# ATmega32U4 register map
File version: 1.0
Registers are 8-bit, read-write, reset 0x0 unless marked. A register's access mark holds for its fields unless they carry their own. Offsets are from the block's base; [hi:lo] are bit positions; {n}, {i} and the like mark numbered series.

## TC4 — Timer/Counter, 10-bit
Base 0x00800000
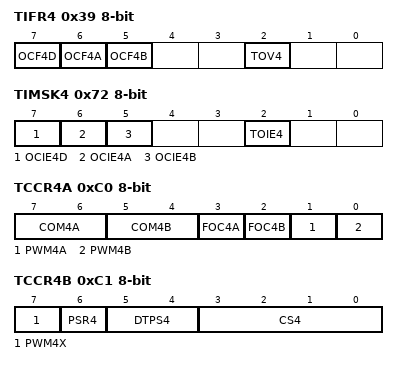
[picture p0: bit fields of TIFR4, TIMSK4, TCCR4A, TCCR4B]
0x39 TIFR4 — Timer/Counter4 Interrupt Flag register
  [7] OCF4D — Output Compare Flag 4D
  [6] OCF4A — Output Compare Flag 4A
  [5] OCF4B — Output Compare Flag 4B
  [2] TOV4 — Timer/Counter4 Overflow Flag
0x72 TIMSK4 — Timer/Counter4 Interrupt Mask Register
  [7] OCIE4D — Timer/Counter4 Output Compare D Match Interrupt Enable
  [6] OCIE4A — Timer/Counter4 Output Compare A Match Interrupt Enable
  [5] OCIE4B — Timer/Counter4 Output Compare B Match Interrupt Enable
  [2] TOIE4 — Timer/Counter4 Overflow Interrupt Enable
0xBE TCNT4 — Timer/Counter4 Low Bytes
0xBF TC4H — Timer/Counter4
0xC0 TCCR4A — Timer/Counter4 Control Register A
  [7:6] COM4A — Compare Output Mode 1A, bits
  [5:4] COM4B — Compare Output Mode 4B, bits
  [3] FOC4A — Force Output Compare Match 4A
  [2] FOC4B — Force Output Compare Match 4B
  [1] PWM4A
  [0] PWM4B
0xC1 TCCR4B — Timer/Counter4 Control Register B
  [7] PWM4X — PWM Inversion Mode
  [6] PSR4 — Prescaler Reset Timer/Counter 4
  [5:4] DTPS4 — Dead Time Prescaler Bits
  [3:0] CS4 — Clock Select Bits
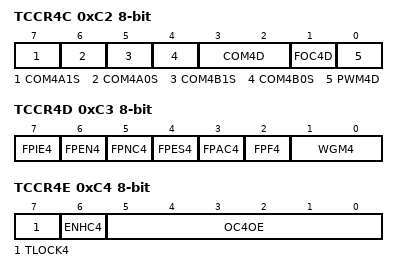
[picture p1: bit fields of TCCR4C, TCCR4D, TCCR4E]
0xC2 TCCR4C — Timer/Counter 4 Control Register C
  [7] COM4A1S — Comparator A Output Mode
  [6] COM4A0S — Comparator A Output Mode
  [5] COM4B1S — Comparator B Output Mode
  [4] COM4B0S — Comparator B Output Mode
  [3:2] COM4D — Comparator D Output Mode
  [1] FOC4D — Force Output Compare Match 4D
  [0] PWM4D — Pulse Width Modulator D Enable
0xC3 TCCR4D — Timer/Counter 4 Control Register D
  [7] FPIE4 — Fault Protection Interrupt Enable
  [6] FPEN4 — Fault Protection Mode Enable
  [5] FPNC4 — Fault Protection Noise Canceler
  [4] FPES4 — Fault Protection Edge Select
  [3] FPAC4 — Fault Protection Analog Comparator Enable
  [2] FPF4 — Fault Protection Interrupt Flag
  [1:0] WGM4 — Waveform Generation Mode bits
0xC4 TCCR4E — Timer/Counter 4 Control Register E
  [7] TLOCK4 — Register Update Lock
  [6] ENHC4 — Enhanced Compare/PWM Mode
  [5:0] OC4OE — Output Compare Override Enable bit

## TC4_2 — Timer/Counter, 10-bit
Base 0x00800000
0xCF OCR4A — Timer/Counter4 Output Compare Register A
0xD0 OCR4B — Timer/Counter4 Output Compare Register B
0xD1 OCR4C — Timer/Counter4 Output Compare Register C
0xD2 OCR4D — Timer/Counter4 Output Compare Register D
0xD4 DT4 — Timer/Counter 4 Dead Time Value
  [7:0] DT4L — Timer/Counter 4 Dead Time Value Bits

## EXINT — External Interrupts
Base 0x00800000
0x3B PCIFR — Pin Change Interrupt Flag Register
  [0] PCIF0 — Pin Change Interrupt Flag 0
0x3C EIFR — External Interrupt Flag Register
  [7:0] INTF — External Interrupt Flags
0x3D EIMSK — External Interrupt Mask Register
  [7:0] INT — External Interrupt Request 7 Enable

## EXINT_2 — External Interrupts
Base 0x00800000
0x68 PCICR — Pin Change Interrupt Control Register
  [0] PCIE0 — Pin Change Interrupt Enable 0
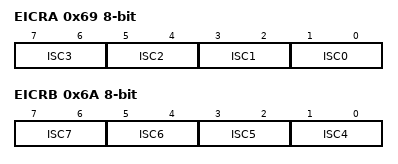
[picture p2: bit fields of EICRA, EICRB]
0x69 EICRA — External Interrupt Control Register A
  [2n+1:2n] ISC{n} (n=0..3) — External Interrupt Sense Control Bit
0x6A EICRB — External Interrupt Control Register B
  [2n-7:2n-8] ISC{n} (n=4..7) — External Interrupt 7-4 Sense Control Bit
0x6B PCMSK0 — Pin Change Mask Register 0

## TWI — Two Wire Serial Interface
Base 0x00800000
0xB8 TWBR — TWI Bit Rate register
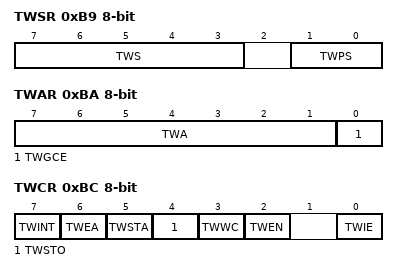
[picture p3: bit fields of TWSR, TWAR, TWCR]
0xB9 TWSR — TWI Status Register
  [7:3] TWS — TWI Status
  [1:0] TWPS — TWI Prescaler
0xBA TWAR — TWI (Slave) Address register
  [7:1] TWA — TWI (Slave) Address register Bits
  [0] TWGCE — TWI General Call Recognition Enable Bit
0xBB TWDR — TWI Data register
0xBC TWCR — TWI Control Register
  [7] TWINT — TWI Interrupt Flag
  [6] TWEA — TWI Enable Acknowledge Bit
  [5] TWSTA — TWI Start Condition Bit
  [4] TWSTO — TWI Stop Condition Bit
  [3] TWWC — TWI Write Collition Flag
  [2] TWEN — TWI Enable Bit
  [0] TWIE — TWI Interrupt Enable
0xBD TWAMR — TWI (Slave) Address Mask Register
  [7:1] TWAM

## ADC — Analog-to-Digital Converter
Base 0x00800000
0x78 ADC 16-bit (reset mask 0xFF) — ADC Data Register Bytes
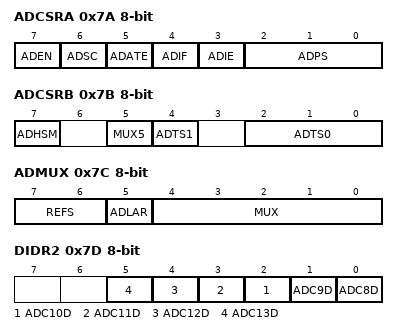
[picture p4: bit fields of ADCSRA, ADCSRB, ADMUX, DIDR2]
0x7A ADCSRA — The ADC Control and Status register
  [7] ADEN — ADC Enable
  [6] ADSC — ADC Start Conversion
  [5] ADATE — ADC Auto Trigger Enable
  [4] ADIF — ADC Interrupt Flag
  [3] ADIE — ADC Interrupt Enable
  [2:0] ADPS — ADC Prescaler Select Bits
0x7B ADCSRB — ADC Control and Status Register B
  [7] ADHSM — ADC High Speed Mode
  [5] MUX5 — Analog Channel and Gain Selection Bits
  [4] ADTS1 — ADC Auto Trigger Sources
  [2:0] ADTS0 — ADC Auto Trigger Sources
0x7C ADMUX — The ADC multiplexer Selection Register
  [7:6] REFS — Reference Selection Bits
  [5] ADLAR — Left Adjust Result
  [4:0] MUX — Analog Channel and Gain Selection Bits
0x7D DIDR2 — Digital Input Disable Register 2
  [n-8] ADC{n}D (n=8..13) — ADC{n} Digital input Disable
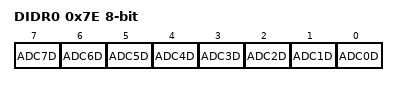
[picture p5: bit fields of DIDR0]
0x7E DIDR0 — Digital Input Disable Register 0
  [n] ADC{n}D (n=0..7) — ADC{n} Digital input Disable

## AC — Analog Comparator
Base 0x00800000
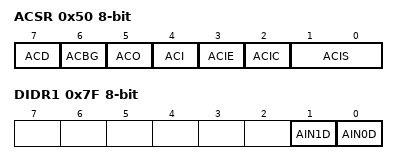
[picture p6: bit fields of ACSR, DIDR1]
0x50 ACSR — Analog Comparator Control And Status Register
  [7] ACD — Analog Comparator Disable
  [6] ACBG — Analog Comparator Bandgap Select
  [5] ACO — Analog Compare Output
  [4] ACI — Analog Comparator Interrupt Flag
  [3] ACIE — Analog Comparator Interrupt Enable
  [2] ACIC — Analog Comparator Input Capture Enable
  [1:0] ACIS — Analog Comparator Interrupt Mode Select bits
0x7B ADCSRB — ADC Control and Status Register B
  [6] ACME — Analog Comparator Multiplexer Enable
0x7F DIDR1
  [1] AIN1D — AIN1 Digital Input Disable
  [0] AIN0D — AIN0 Digital Input Disable

## PLL — Phase Locked Loop
Base 0x00800000
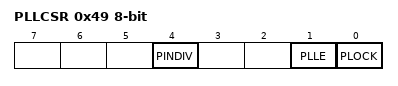
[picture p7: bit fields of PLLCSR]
0x49 PLLCSR ro — PLL Status and Control register
  [4] PINDIV — PLL prescaler Bit 2
  [1] PLLE — PLL Enable Bit
  [0] PLOCK — PLL Lock Status Bit

## PLL_2 — Phase Locked Loop
Base 0x00800000
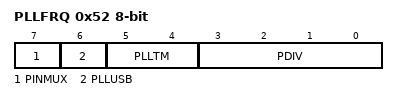
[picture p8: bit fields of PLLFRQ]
0x52 PLLFRQ ro — PLL Frequency Control Register
  [7] PINMUX, [6] PLLUSB, [5:4] PLLTM, [3:0] PDIV
